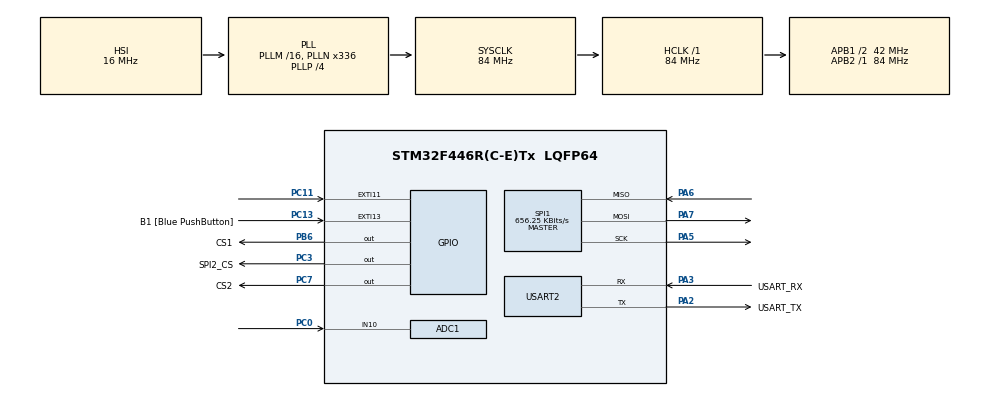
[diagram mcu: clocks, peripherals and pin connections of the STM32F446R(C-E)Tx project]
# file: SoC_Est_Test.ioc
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ADC1.Channel-0\#ChannelRegularConversion=ADC_CHANNEL_10
ADC1.ContinuousConvMode=ENABLE
ADC1.DMAContinuousRequests=ENABLE
ADC1.NbrOfConversionFlag=1
ADC1.Rank-0\#ChannelRegularConversion=1
ADC1.SamplingTime-0\#ChannelRegularConversion=ADC_SAMPLETIME_3CYCLES
ADC1.master=1
Dma.ADC1.0.Direction=DMA_PERIPH_TO_MEMORY
Dma.ADC1.0.FIFOMode=DMA_FIFOMODE_DISABLE
Dma.ADC1.0.Instance=DMA2_Stream0
Dma.ADC1.0.MemDataAlignment=DMA_MDATAALIGN_HALFWORD
Dma.ADC1.0.MemInc=DMA_MINC_ENABLE
Dma.ADC1.0.Mode=DMA_CIRCULAR
Dma.ADC1.0.PeriphDataAlignment=DMA_PDATAALIGN_HALFWORD
Dma.ADC1.0.PeriphInc=DMA_PINC_DISABLE
Dma.ADC1.0.Priority=DMA_PRIORITY_LOW
Dma.Request0=ADC1
Mcu.Family=STM32F4
Mcu.Name=STM32F446R(C-E)Tx
Mcu.Package=LQFP64
NVIC.DMA2_Stream0_IRQn=true\:0\:0\:false\:false\:true\:false\:true
NVIC.PriorityGroup=NVIC_PRIORITYGROUP_0
NVIC.TIM8_BRK_TIM12_IRQn=true\:0\:0\:false\:false\:true\:true\:true
NVIC.TIM8_TRG_COM_TIM14_IRQn=true\:0\:0\:false\:false\:true\:true\:true
NVIC.TIM8_UP_TIM13_IRQn=true\:0\:1\:false\:false\:true\:true\:true
PA13.GPIO_Label=TMS
PA13.Mode=Serial_Wire
PA13.Signal=SYS_JTMS-SWDIO
PA14.GPIO_Label=TCK
PA14.Mode=Serial_Wire
PA14.Signal=SYS_JTCK-SWCLK
PA2.GPIO_Label=USART_TX
PA2.Mode=Asynchronous
PA2.Signal=USART2_TX
PA3.GPIO_Label=USART_RX
PA3.Mode=Asynchronous
PA3.Signal=USART2_RX
PA5.Mode=Full_Duplex_Master
PA5.Signal=SPI1_SCK
PA6.Mode=Full_Duplex_Master
PA6.Signal=SPI1_MISO
PA7.Mode=Full_Duplex_Master
PA7.Signal=SPI1_MOSI
PB3.GPIO_Label=SWO
PB3.Signal=SYS_JTDO-SWO
PB6.GPIO_Label=CS1
PB6.Signal=GPIO_Output
PC0.Signal=ADCx_IN10
PC11.Signal=GPXTI11
PC13.GPIO_Label=B1 [Blue PushButton]
PC13.GPIO_ModeDefaultEXTI=GPIO_MODE_IT_FALLING
PC13.Signal=GPXTI13
PC14-OSC32_IN.Mode=LSE-External-Oscillator
PC14-OSC32_IN.Signal=RCC_OSC32_IN
PC15-OSC32_OUT.Mode=LSE-External-Oscillator
PC15-OSC32_OUT.Signal=RCC_OSC32_OUT
PC3.GPIO_Label=SPI2_CS
PC3.Signal=GPIO_Output
PC7.GPIO_Label=CS2
PC7.Signal=GPIO_Output
PH0-OSC_IN.Mode=HSE-External-Oscillator
PH0-OSC_IN.Signal=RCC_OSC_IN
PH1-OSC_OUT.Mode=HSE-External-Oscillator
PH1-OSC_OUT.Signal=RCC_OSC_OUT
ProjectManager.HeapSize=0x200
ProjectManager.StackSize=0x400
ProjectManager.TargetToolchain=STM32CubeIDE
RCC.48MHZClocksFreq_Value=84000000
RCC.AHBFreq_Value=84000000
RCC.APB1CLKDivider=RCC_HCLK_DIV2
RCC.APB1Freq_Value=42000000
RCC.APB1TimFreq_Value=84000000
RCC.APB2Freq_Value=84000000
RCC.APB2TimFreq_Value=84000000
RCC.CortexFreq_Value=84000000
RCC.FLatency-AdvancedSettings=FLASH_LATENCY_2
RCC.HCLKFreq_Value=84000000
RCC.HSE_VALUE=8000000
RCC.HSI_VALUE=16000000
RCC.PLLN=336
RCC.PLLP=RCC_PLLP_DIV4
RCC.SYSCLKFreq_VALUE=84000000
RCC.SYSCLKSource=RCC_SYSCLKSOURCE_PLLCLK
RCC.USBFreq_Value=168000000
RCC.VCOOutputFreq_Value=336000000
SH.ADCx_IN10.0=ADC1_IN10,IN10
SPI1.BaudRatePrescaler=SPI_BAUDRATEPRESCALER_128
SPI1.CalculateBaudRate=656.25 KBits/s
SPI1.Direction=SPI_DIRECTION_2LINES
SPI1.Mode=SPI_MODE_MASTER
SPI1.VirtualType=VM_MASTER
TIM11.Prescaler=84-1
TIM12.Period=12500-1
TIM12.Prescaler=33600-1
TIM13.Period=10000-1
TIM13.Prescaler=8400-1
TIM14.Period=1000-1
TIM14.Prescaler=8400-1
USART2.VirtualMode=VM_ASYNC
VP_TIM11_VS_ClockSourceINT.Mode=Enable_Timer
VP_TIM12_VS_ClockSourceINT.Mode=Internal
VP_TIM13_VS_ClockSourceINT.Mode=Enable_Timer
VP_TIM14_VS_ClockSourceINT.Mode=Enable_Timer
board=NUCLEO-F446RE

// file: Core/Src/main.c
/* USER CODE BEGIN Header */
/**
  ******************************************************************************
  * @file           : main.c
  * @brief          : Main program body
  ******************************************************************************
  * @attention
  *
  * <h2><center>&copy; Copyright (c) 2022 STMicroelectronics.
  * All rights reserved.</center></h2>
  *
  * This software component is licensed by ST under BSD 3-Clause license,
  * the "License"; You may not use this file except in compliance with the
  * License. You may obtain a copy of the License at:
  *                        opensource.org/licenses/BSD-3-Clause
  *
  ******************************************************************************
  */
/* USER CODE END Header */
#include "main.h"

/* USER CODE BEGIN Includes */
#include <stdio.h>
/* USER CODE END Includes */

#define ADC_BUF_LEN 4096

ADC_HandleTypeDef hadc1;
DMA_HandleTypeDef hdma_adc1;

SPI_HandleTypeDef hspi1;

TIM_HandleTypeDef htim11;
TIM_HandleTypeDef htim12;
TIM_HandleTypeDef htim13;
TIM_HandleTypeDef htim14;

UART_HandleTypeDef huart2;

/* USER CODE BEGIN PV */
uint16_t adc_buf[ADC_BUF_LEN];
/* USER CODE END PV */

void SystemClock_Config(void);
static void MX_GPIO_Init(void);
static void MX_USART2_UART_Init(void);
static void MX_TIM13_Init(void);
static void MX_SPI1_Init(void);
static void MX_TIM14_Init(void);
static void MX_TIM11_Init(void);
static void MX_ADC1_Init(void);
static void MX_DMA_Init(void);
static void MX_TIM12_Init(void);

int main(void)
{

  /* MCU Configuration--------------------------------------------------------*/

  /* Reset of all peripherals, Initializes the Flash interface and the Systick. */
  HAL_Init();

  /* Configure the system clock */
  SystemClock_Config();

  /* Initialize all configured peripherals */
  MX_GPIO_Init();
  MX_USART2_UART_Init();
  MX_TIM13_Init();
  MX_SPI1_Init();
  MX_TIM14_Init();
  MX_TIM11_Init();
  MX_ADC1_Init();
  MX_DMA_Init();
  MX_TIM12_Init();
  /* USER CODE BEGIN 2 */
  //HAL_TIM_Base_Start_IT(&htim14);
  HAL_ADC_Start_DMA(&hadc1, (uint32_t*)adc_buf, ADC_BUF_LEN);
  /* USER CODE END 2 */

  /* Infinite loop */
  /* USER CODE BEGIN WHILE */
  while (1)
  {
	  HAL_Delay(10);
    /* USER CODE END WHILE */

  }
}

void SystemClock_Config(void)
{
  RCC_OscInitTypeDef RCC_OscInitStruct = {0};
  RCC_ClkInitTypeDef RCC_ClkInitStruct = {0};

  /** Configure the main internal regulator output voltage
  */
  __HAL_RCC_PWR_CLK_ENABLE();
  __HAL_PWR_VOLTAGESCALING_CONFIG(PWR_REGULATOR_VOLTAGE_SCALE3);
  /** Initializes the RCC Oscillators according to the specified parameters
  * in the RCC_OscInitTypeDef structure.
  */
  RCC_OscInitStruct.OscillatorType = RCC_OSCILLATORTYPE_HSI;
  RCC_OscInitStruct.HSIState = RCC_HSI_ON;
  RCC_OscInitStruct.HSICalibrationValue = RCC_HSICALIBRATION_DEFAULT;
  RCC_OscInitStruct.PLL.PLLState = RCC_PLL_ON;
  RCC_OscInitStruct.PLL.PLLSource = RCC_PLLSOURCE_HSI;
  RCC_OscInitStruct.PLL.PLLM = 16;
  RCC_OscInitStruct.PLL.PLLN = 336;
  RCC_OscInitStruct.PLL.PLLP = RCC_PLLP_DIV4;
  RCC_OscInitStruct.PLL.PLLQ = 2;
  RCC_OscInitStruct.PLL.PLLR = 2;
  if (HAL_RCC_OscConfig(&RCC_OscInitStruct) != HAL_OK)
  {
    Error_Handler();
  }
  /** Initializes the CPU, AHB and APB buses clocks
  */
  RCC_ClkInitStruct.ClockType = RCC_CLOCKTYPE_HCLK|RCC_CLOCKTYPE_SYSCLK
                              |RCC_CLOCKTYPE_PCLK1|RCC_CLOCKTYPE_PCLK2;
  RCC_ClkInitStruct.SYSCLKSource = RCC_SYSCLKSOURCE_PLLCLK;
  RCC_ClkInitStruct.AHBCLKDivider = RCC_SYSCLK_DIV1;
  RCC_ClkInitStruct.APB1CLKDivider = RCC_HCLK_DIV2;
  RCC_ClkInitStruct.APB2CLKDivider = RCC_HCLK_DIV1;

  if (HAL_RCC_ClockConfig(&RCC_ClkInitStruct, FLASH_LATENCY_2) != HAL_OK)
  {
    Error_Handler();
  }
}

static void MX_ADC1_Init(void)
{

  ADC_ChannelConfTypeDef sConfig = {0};

  /** Configure the global features of the ADC (Clock, Resolution, Data Alignment and number of conversion)
  */
  hadc1.Instance = ADC1;
  hadc1.Init.ClockPrescaler = ADC_CLOCK_SYNC_PCLK_DIV4;
  hadc1.Init.Resolution = ADC_RESOLUTION_12B;
  hadc1.Init.ScanConvMode = DISABLE;
  hadc1.Init.ContinuousConvMode = ENABLE;
  hadc1.Init.DiscontinuousConvMode = DISABLE;
  hadc1.Init.ExternalTrigConvEdge = ADC_EXTERNALTRIGCONVEDGE_NONE;
  hadc1.Init.ExternalTrigConv = ADC_SOFTWARE_START;
  hadc1.Init.DataAlign = ADC_DATAALIGN_RIGHT;
  hadc1.Init.NbrOfConversion = 1;
  hadc1.Init.DMAContinuousRequests = ENABLE;
  hadc1.Init.EOCSelection = ADC_EOC_SINGLE_CONV;
  if (HAL_ADC_Init(&hadc1) != HAL_OK)
  {
    Error_Handler();
  }
  /** Configure for the selected ADC regular channel its corresponding rank in the sequencer and its sample time.
  */
  sConfig.Channel = ADC_CHANNEL_10;
  sConfig.Rank = 1;
  sConfig.SamplingTime = ADC_SAMPLETIME_3CYCLES;
  if (HAL_ADC_ConfigChannel(&hadc1, &sConfig) != HAL_OK)
  {
    Error_Handler();
  }

}

static void MX_SPI1_Init(void)
{

  /* SPI1 parameter configuration*/
  hspi1.Instance = SPI1;
  hspi1.Init.Mode = SPI_MODE_MASTER;
  hspi1.Init.Direction = SPI_DIRECTION_2LINES;
  hspi1.Init.DataSize = SPI_DATASIZE_8BIT;
  hspi1.Init.CLKPolarity = SPI_POLARITY_LOW;
  hspi1.Init.CLKPhase = SPI_PHASE_1EDGE;
  hspi1.Init.NSS = SPI_NSS_SOFT;
  hspi1.Init.BaudRatePrescaler = SPI_BAUDRATEPRESCALER_128;
  hspi1.Init.FirstBit = SPI_FIRSTBIT_MSB;
  hspi1.Init.TIMode = SPI_TIMODE_DISABLE;
  hspi1.Init.CRCCalculation = SPI_CRCCALCULATION_DISABLE;
  hspi1.Init.CRCPolynomial = 10;
  if (HAL_SPI_Init(&hspi1) != HAL_OK)
  {
    Error_Handler();
  }

}

static void MX_TIM11_Init(void)
{

  htim11.Instance = TIM11;
  htim11.Init.Prescaler = 84-1;
  htim11.Init.CounterMode = TIM_COUNTERMODE_UP;
  htim11.Init.Period = 65535;
  htim11.Init.ClockDivision = TIM_CLOCKDIVISION_DIV1;
  htim11.Init.AutoReloadPreload = TIM_AUTORELOAD_PRELOAD_DISABLE;
  if (HAL_TIM_Base_Init(&htim11) != HAL_OK)
  {
    Error_Handler();
  }

}

static void MX_TIM12_Init(void)
{

  TIM_ClockConfigTypeDef sClockSourceConfig = {0};

  htim12.Instance = TIM12;
  htim12.Init.Prescaler = 33600-1;
  htim12.Init.CounterMode = TIM_COUNTERMODE_UP;
  htim12.Init.Period = 12500-1;
  htim12.Init.ClockDivision = TIM_CLOCKDIVISION_DIV1;
  htim12.Init.AutoReloadPreload = TIM_AUTORELOAD_PRELOAD_DISABLE;
  if (HAL_TIM_Base_Init(&htim12) != HAL_OK)
  {
    Error_Handler();
  }
  sClockSourceConfig.ClockSource = TIM_CLOCKSOURCE_INTERNAL;
  if (HAL_TIM_ConfigClockSource(&htim12, &sClockSourceConfig) != HAL_OK)
  {
    Error_Handler();
  }

}

static void MX_TIM13_Init(void)
{

  htim13.Instance = TIM13;
  htim13.Init.Prescaler = 8400-1;
  htim13.Init.CounterMode = TIM_COUNTERMODE_UP;
  htim13.Init.Period = 10000-1;
  htim13.Init.ClockDivision = TIM_CLOCKDIVISION_DIV1;
  htim13.Init.AutoReloadPreload = TIM_AUTORELOAD_PRELOAD_DISABLE;
  if (HAL_TIM_Base_Init(&htim13) != HAL_OK)
  {
    Error_Handler();
  }

}

static void MX_TIM14_Init(void)
{

  htim14.Instance = TIM14;
  htim14.Init.Prescaler = 8400-1;
  htim14.Init.CounterMode = TIM_COUNTERMODE_UP;
  htim14.Init.Period = 1000-1;
  htim14.Init.ClockDivision = TIM_CLOCKDIVISION_DIV1;
  htim14.Init.AutoReloadPreload = TIM_AUTORELOAD_PRELOAD_DISABLE;
  if (HAL_TIM_Base_Init(&htim14) != HAL_OK)
  {
    Error_Handler();
  }

}

static void MX_USART2_UART_Init(void)
{

  huart2.Instance = USART2;
  huart2.Init.BaudRate = 115200;
  huart2.Init.WordLength = UART_WORDLENGTH_8B;
  huart2.Init.StopBits = UART_STOPBITS_1;
  huart2.Init.Parity = UART_PARITY_NONE;
  huart2.Init.Mode = UART_MODE_TX_RX;
  huart2.Init.HwFlowCtl = UART_HWCONTROL_NONE;
  huart2.Init.OverSampling = UART_OVERSAMPLING_16;
  if (HAL_UART_Init(&huart2) != HAL_OK)
  {
    Error_Handler();
  }

}

static void MX_DMA_Init(void)
{

  /* DMA controller clock enable */
  __HAL_RCC_DMA2_CLK_ENABLE();

  /* DMA interrupt init */
  /* DMA2_Stream0_IRQn interrupt configuration */
  HAL_NVIC_SetPriority(DMA2_Stream0_IRQn, 0, 0);
  HAL_NVIC_EnableIRQ(DMA2_Stream0_IRQn);

}

static void MX_GPIO_Init(void)
{
  GPIO_InitTypeDef GPIO_InitStruct = {0};

  /* GPIO Ports Clock Enable */
  __HAL_RCC_GPIOC_CLK_ENABLE();
  __HAL_RCC_GPIOH_CLK_ENABLE();
  __HAL_RCC_GPIOA_CLK_ENABLE();
  __HAL_RCC_GPIOB_CLK_ENABLE();

  /*Configure GPIO pin Output Level */
  HAL_GPIO_WritePin(GPIOC, SPI2_CS_Pin|CS2_Pin, GPIO_PIN_RESET);

  /*Configure GPIO pin Output Level */
  HAL_GPIO_WritePin(CS1_GPIO_Port, CS1_Pin, GPIO_PIN_RESET);

  /*Configure GPIO pin : B1_Pin */
  GPIO_InitStruct.Pin = B1_Pin;
  GPIO_InitStruct.Mode = GPIO_MODE_IT_FALLING;
  GPIO_InitStruct.Pull = GPIO_NOPULL;
  HAL_GPIO_Init(B1_GPIO_Port, &GPIO_InitStruct);

  /*Configure GPIO pins : SPI2_CS_Pin CS2_Pin */
  GPIO_InitStruct.Pin = SPI2_CS_Pin|CS2_Pin;
  GPIO_InitStruct.Mode = GPIO_MODE_OUTPUT_PP;
  GPIO_InitStruct.Pull = GPIO_NOPULL;
  GPIO_InitStruct.Speed = GPIO_SPEED_FREQ_LOW;
  HAL_GPIO_Init(GPIOC, &GPIO_InitStruct);

  /*Configure GPIO pin : PC11 */
  GPIO_InitStruct.Pin = GPIO_PIN_11;
  GPIO_InitStruct.Mode = GPIO_MODE_IT_RISING;
  GPIO_InitStruct.Pull = GPIO_NOPULL;
  HAL_GPIO_Init(GPIOC, &GPIO_InitStruct);

  /*Configure GPIO pin : CS1_Pin */
  GPIO_InitStruct.Pin = CS1_Pin;
  GPIO_InitStruct.Mode = GPIO_MODE_OUTPUT_PP;
  GPIO_InitStruct.Pull = GPIO_NOPULL;
  GPIO_InitStruct.Speed = GPIO_SPEED_FREQ_LOW;
  HAL_GPIO_Init(CS1_GPIO_Port, &GPIO_InitStruct);

}

/* USER CODE BEGIN 4 */
void HAL_ADC_ConvCpltCallback(ADC_HandleTypeDef* hadc) {
  int x=0;
	//HAL_GPIO_WritePin(LD2_GPIO_Port, LD2_Pin, GPIO_PIN_RESET);
}

void HAL_TIM_PeriodElapsedCallback(TIM_HandleTypeDef *htim){
	/*if(htim == &htim14){		//100ms t
		uint16_t packCurrent;
		uint8_t numSample=50;
		uint32_t raw_sum=0;
		//HAL_TIM_Base_Start(&htim13);
		//__HAL_TIM_SetCounter(&htim13,0);
		for(int ii=0; ii<numSample; ii++){
			HAL_ADC_Start(&hadc1);
			HAL_ADC_PollForConversion(&hadc1, HAL_MAX_DELAY);
			raw_sum += HAL_ADC_GetValue(&hadc1)*3300/4095;
		}
		//uint32_t tim_Val = __HAL_TIM_GetCounter(&htim13);
		uint16_t avg = raw_sum/numSample;
		packCurrent = (avg-2500)/0.04;
		int str_len;
		char cell_I[18];
		str_len = snprintf(cell_I, 8, "%d\r\n",packCurrent);
		HAL_UART_Transmit(&huart2, (int *)cell_I, str_len, 100);
	}*/
}
/* USER CODE END 4 */

void Error_Handler(void)
{
  __disable_irq();
  while (1)
  {
  }
}

/************************ (C) COPYRIGHT STMicroelectronics *****END OF FILE****/
